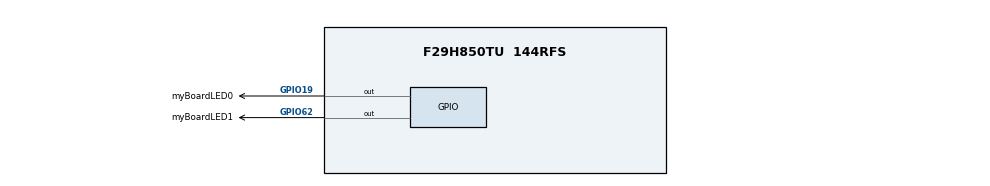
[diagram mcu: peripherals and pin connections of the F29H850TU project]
/**
 * These arguments were used when this file was generated. They will be automatically applied on subsequent loads
 * via the GUI or CLI. Run CLI with '--help' for additional information on how to override these arguments.
 * @cliArgs --device "F29H85x" --part "F29H85x_144RFS" --package "144RFS" --context "CPU1" --product "MCU_SDK_F29H85x@1.00.00.00"
 * @v2CliArgs --device "F29H850TU" --package "144RFS" --variant "TMS320F29H850TU9" --context "CPU1" --product "MCU_SDK_F29H85x@1.00.00.00"
 * @versions {"tool":"1.22.0+3877"}
 */

const divider15       = system.clockTree["PLL_REFDIV"];
divider15.divideValue = 1;

const multiplier1         = system.clockTree["PLL_IMULT"];
multiplier1.multiplyValue = 40;

const mux7       = system.clockTree["OSCCLKSRCSEL"];
mux7.inputSelect = "INTOSC2";

/**
 * Import the modules used in this configuration.
 */
const led  = scripting.addModule("/driverlib/board_components/led", {}, false);
const led1 = led.addInstance();
const led2 = led.addInstance();
const jtag = scripting.addModule("/driverlib/jtag.js");

/**
 * Write custom configuration values to the imported modules.
 */
led1.$name                  = "myBoardLED0";
led1.gpio.writeInitialValue = true;
led1.gpio.initialValue      = 1;
led1.gpio.gpioPin.$assign   = "GPIO19";

led2.$name                  = "myBoardLED1";
led2.gpio.writeInitialValue = true;
led2.gpio.gpioPin.$assign   = "GPIO62";

